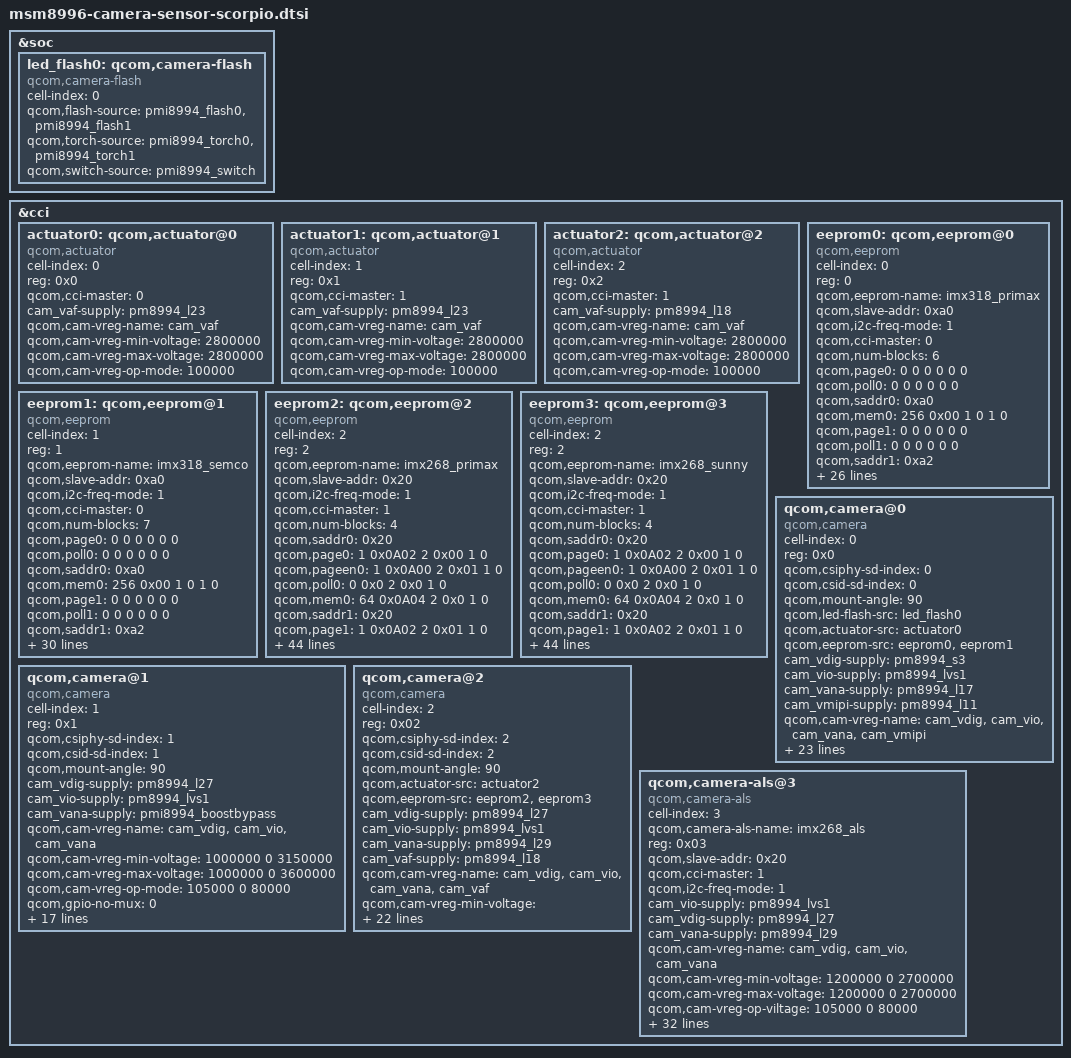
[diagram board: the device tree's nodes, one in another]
/*
 * Copyright (c) 2015-2016, The Linux Foundation. All rights reserved.
 * Copyright (C) 2016 XiaoMi, Inc.
 *
 * This program is free software; you can redistribute it and/or modify
 * it under the terms of the GNU General Public License version 2 and
 * only version 2 as published by the Free Software Foundation.
 *
 * This program is distributed in the hope that it will be useful,
 * but WITHOUT ANY WARRANTY; without even the implied warranty of
 * MERCHANTABILITY or FITNESS FOR A PARTICULAR PURPOSE.  See the
 * GNU General Public License for more details.
 */

&soc {
	led_flash0: qcom,camera-flash {
		cell-index = <0>;
		compatible = "qcom,camera-flash";
		qcom,flash-source = <&pmi8994_flash0 &pmi8994_flash1>;
		qcom,torch-source = <&pmi8994_torch0 &pmi8994_torch1>;
		qcom,switch-source = <&pmi8994_switch>;
	};
};

&cci {
	actuator0: qcom,actuator@0 {
		cell-index = <0>;
		reg = <0x0>;
		compatible = "qcom,actuator";
		qcom,cci-master = <0>;
		cam_vaf-supply = <&pm8994_l23>;
		qcom,cam-vreg-name = "cam_vaf";
		qcom,cam-vreg-min-voltage = <2800000>;
		qcom,cam-vreg-max-voltage = <2800000>;
		qcom,cam-vreg-op-mode = <100000>;
	};

	actuator1: qcom,actuator@1 {
		cell-index = <1>;
		reg = <0x1>;
		compatible = "qcom,actuator";
		qcom,cci-master = <1>;
		cam_vaf-supply = <&pm8994_l23>;
		qcom,cam-vreg-name = "cam_vaf";
		qcom,cam-vreg-min-voltage = <2800000>;
		qcom,cam-vreg-max-voltage = <2800000>;
		qcom,cam-vreg-op-mode = <100000>;
	};

	actuator2: qcom,actuator@2 {
		cell-index = <2>;
		reg = <0x2>;
		compatible = "qcom,actuator";
		qcom,cci-master = <1>;
		cam_vaf-supply = <&pm8994_l18>;
		qcom,cam-vreg-name = "cam_vaf";
		qcom,cam-vreg-min-voltage = <2800000>;
		qcom,cam-vreg-max-voltage = <2800000>;
		qcom,cam-vreg-op-mode = <100000>;
	};

	eeprom0: qcom,eeprom@0 {
		cell-index = <0>;
		reg = <0>;
		qcom,eeprom-name = "imx318_primax";
		compatible = "qcom,eeprom";
		qcom,slave-addr = <0xa0>;
		qcom,i2c-freq-mode = <1>;
		qcom,cci-master = <0>;
		qcom,num-blocks = <6>;

		qcom,page0 = <0 0 0 0 0 0>;
		qcom,poll0 = <0 0 0 0 0 0>;
		qcom,saddr0 = <0xa0>;
		qcom,mem0 = <256 0x00 1 0 1 0>;

		qcom,page1 = <0 0 0 0 0 0>;
		qcom,poll1 = <0 0 0 0 0 0>;
		qcom,saddr1 = <0xa2>;
		qcom,mem1 = <256 0x00 1 0 1 0>;

		qcom,page2 = <0 0 0 0 0 0>;
		qcom,poll2 = <0 0 0 0 0 0>;
		qcom,saddr2 = <0xa4>;
		qcom,mem2 = <256 0x00 1 0 1 0>;

		qcom,page3 = <0 0 0 0 0 0>;
		qcom,poll3 = <0 0 0 0 0 0>;
		qcom,saddr3 = <0xa6>;
		qcom,mem3 = <256 0x00 1 0 1 0>;

		qcom,page4 = <0 0 0 0 0 0>;
		qcom,poll4 = <0 0 0 0 0 0>;
		qcom,saddr4 = <0xa8>;
		qcom,mem4 = <256 0x00 1 0 1 0>;

		qcom,page5 = <0 0 0 0 0 0>;
		qcom,poll5 = <0 0 0 0 0 0>;
		qcom,saddr5 = <0xaa>;
		qcom,mem5 = <100 0x00 1 0 1 0>;

		cam_vio-supply = <&pm8994_lvs1>;
		qcom,cam-vreg-name = "cam_vio";
		qcom,cam-vreg-min-voltage = <0>;
		qcom,cam-vreg-max-voltage = <0>;
		qcom,cam-vreg-op-mode = <0>;
		qcom,cam-power-seq-type = "sensor_vreg";
		qcom,cam-power-seq-val = "cam_vio";
		qcom,cam-power-seq-cfg-val = <1>;
		qcom,cam-power-seq-delay = <1>;
	};

	eeprom1: qcom,eeprom@1 {
		cell-index = <1>;
		reg = <1>;
		qcom,eeprom-name = "imx318_semco";
		compatible = "qcom,eeprom";
		qcom,slave-addr = <0xa0>;
		qcom,i2c-freq-mode = <1>;
		qcom,cci-master = <0>;
		qcom,num-blocks = <7>;

		qcom,page0 = <0 0 0 0 0 0>;
		qcom,poll0 = <0 0 0 0 0 0>;
		qcom,saddr0 = <0xa0>;
		qcom,mem0 = <256 0x00 1 0 1 0>;

		qcom,page1 = <0 0 0 0 0 0>;
		qcom,poll1 = <0 0 0 0 0 0>;
		qcom,saddr1 = <0xa2>;
		qcom,mem1 = <256 0x00 1 0 1 0>;

		qcom,page2 = <0 0 0 0 0 0>;
		qcom,poll2 = <0 0 0 0 0 0>;
		qcom,saddr2 = <0xa4>;
		qcom,mem2 = <256 0x00 1 0 1 0>;

		qcom,page3 = <0 0 0 0 0 0>;
		qcom,poll3 = <0 0 0 0 0 0>;
		qcom,saddr3 = <0xa6>;
		qcom,mem3 = <256 0x00 1 0 1 0>;

		qcom,page4 = <0 0 0 0 0 0>;
		qcom,poll4 = <0 0 0 0 0 0>;
		qcom,saddr4 = <0xa8>;
		qcom,mem4 = <256 0x00 1 0 1 0>;

		qcom,page5 = <0 0 0 0 0 0>;
		qcom,poll5 = <0 0 0 0 0 0>;
		qcom,saddr5 = <0xaa>;
		qcom,mem5 = <256 0x00 1 0 1 0>;

		qcom,page6 = <0 0 0 0 0 0>;
		qcom,poll6 = <0 0 0 0 0 0>;
		qcom,saddr6 = <0xac>;
		qcom,mem6 = <256 0x00 1 0 1 0>;

		cam_vio-supply = <&pm8994_lvs1>;
		qcom,cam-vreg-name = "cam_vio";
		qcom,cam-vreg-min-voltage = <0>;
		qcom,cam-vreg-max-voltage = <0>;
		qcom,cam-vreg-op-mode = <0>;
		qcom,cam-power-seq-type = "sensor_vreg";
		qcom,cam-power-seq-val = "cam_vio";
		qcom,cam-power-seq-cfg-val = <1>;
		qcom,cam-power-seq-delay = <1>;
	};

	eeprom2: qcom,eeprom@2 {
		cell-index = <2>;
		reg = <2>;
		qcom,eeprom-name = "imx268_primax";
		compatible = "qcom,eeprom";
		qcom,slave-addr = <0x20>;
		qcom,i2c-freq-mode = <1>;
		qcom,cci-master = <1>;
		qcom,num-blocks = <4>;

		qcom,saddr0 = <0x20>;
		qcom,page0 = <1 0x0A02 2 0x00 1 0>;
		qcom,pageen0 = <1 0x0A00 2 0x01 1 0>;
		qcom,poll0 = <0 0x0 2 0x0 1 0>;
		qcom,mem0 = <64 0x0A04 2 0x0 1 0>;

	        qcom,saddr1 = <0x20>;
		qcom,page1 = <1 0x0A02 2 0x01 1 0>;
		qcom,pageen1 = <1 0x0A00 2 0x01 1 0>;
		qcom,poll1 = <0 0x0 2 0x0 1 0>;
		qcom,mem1 = <64 0x0A04 2 0x0 1 0>;

	        qcom,saddr2 = <0x20>;
		qcom,page2 = <1 0x0A02 2 0x02 1 0>;
		qcom,pageen2 = <1 0x0A00 2 0x01 1 0>;
		qcom,poll2 = <0 0x0 2 0x0 1 0>;
		qcom,mem2 = <64 0x0A04 2 0x0 1 0>;

	        qcom,saddr3 = <0x20>;
		qcom,page3 = <1 0x0A02 2 0x03 1 0>;
		qcom,pageen3 = <1 0x0A00 2 0x01 1 0>;
		qcom,poll3 = <0 0x0 2 0x0 1 0>;
		qcom,mem3 = <64 0x0A04 2 0x0 1 0>;

		cam_vdig-supply = <&pm8994_l27>;
		cam_vio-supply = <&pm8994_lvs1>;
		cam_vana-supply = <&pm8994_l29>;
		qcom,cam-vreg-name = "cam_vdig", "cam_vio", "cam_vana";
		qcom,cam-vreg-min-voltage = <1200000 0 2700000>;
		qcom,cam-vreg-max-voltage = <1200000 0 2700000>;
		qcom,cam-vreg-op-mode = <105000 0 80000>;
		qcom,gpio-no-mux = <0>;
		pinctrl-names = "cam_default", "cam_suspend";
		pinctrl-0 = <&cam_sensor_mclk2_active &cam_sensor_front_active>;
		pinctrl-1 = <&cam_sensor_mclk2_suspend &cam_sensor_front_suspend>;
		gpios = <&tlmm 15 0>,
			<&tlmm 23 0>,
			<&tlmm 26 0>;
		qcom,gpio-reset = <1>;
		qcom,gpio-standby = <2>;
		qcom,gpio-req-tbl-num = <0 1 2>;
		qcom,gpio-req-tbl-flags = <1 0 0>;
		qcom,gpio-req-tbl-label = "CAMIF_MCLK2",
					  "CAM_RESET2",
					  "VCM_PWDN";
		qcom,cam-power-seq-type = "sensor_vreg", "sensor_vreg", "sensor_vreg",
			"sensor_gpio", "sensor_gpio" , "sensor_clk";
		qcom,cam-power-seq-val = "cam_vdig", "cam_vana", "cam_vio",
			"sensor_gpio_reset", "sensor_gpio_standby","sensor_cam_mclk";
		qcom,cam-power-seq-cfg-val = <1 1 1 1 1 24000000>;
		qcom,cam-power-seq-delay = <1 1 1 30 30 5>;
		status = "ok";
		clocks = <&clock_mmss clk_mclk2_clk_src>,
			 <&clock_mmss clk_camss_mclk2_clk>;
		clock-names = "cam_src_clk", "cam_clk";
		qcom,clock-rates = <24000000 0>;
	};

	eeprom3: qcom,eeprom@3 {
		cell-index = <2>;
		reg = <2>;
		qcom,eeprom-name = "imx268_sunny";
		compatible = "qcom,eeprom";
		qcom,slave-addr = <0x20>;
		qcom,i2c-freq-mode = <1>;
		qcom,cci-master = <1>;
		qcom,num-blocks = <4>;

		qcom,saddr0 = <0x20>;
		qcom,page0 = <1 0x0A02 2 0x00 1 0>;
		qcom,pageen0 = <1 0x0A00 2 0x01 1 0>;
		qcom,poll0 = <0 0x0 2 0x0 1 0>;
		qcom,mem0 = <64 0x0A04 2 0x0 1 0>;

		qcom,saddr1 = <0x20>;
		qcom,page1 = <1 0x0A02 2 0x01 1 0>;
		qcom,pageen1 = <1 0x0A00 2 0x01 1 0>;
		qcom,poll1 = <0 0x0 2 0x0 1 0>;
		qcom,mem1 = <64 0x0A04 2 0x0 1 0>;

		qcom,saddr2 = <0x20>;
		qcom,page2 = <1 0x0A02 2 0x02 1 0>;
		qcom,pageen2 = <1 0x0A00 2 0x01 1 0>;
		qcom,poll2 = <0 0x0 2 0x0 1 0>;
		qcom,mem2 = <64 0x0A04 2 0x0 1 0>;

		qcom,saddr3 = <0x20>;
		qcom,page3 = <1 0x0A02 2 0x03 1 0>;
		qcom,pageen3 = <1 0x0A00 2 0x01 1 0>;
		qcom,poll3 = <0 0x0 2 0x0 1 0>;
		qcom,mem3 = <64 0x0A04 2 0x0 1 0>;

		cam_vdig-supply = <&pm8994_l27>;
		cam_vio-supply = <&pm8994_lvs1>;
		cam_vana-supply = <&pm8994_l29>;
		qcom,cam-vreg-name = "cam_vdig", "cam_vio", "cam_vana";
		qcom,cam-vreg-min-voltage = <1200000 0 2700000>;
		qcom,cam-vreg-max-voltage = <1200000 0 2700000>;
		qcom,cam-vreg-op-mode = <105000 0 80000>;
		qcom,gpio-no-mux = <0>;
		pinctrl-names = "cam_default", "cam_suspend";
		pinctrl-0 = <&cam_sensor_mclk2_active &cam_sensor_front_active>;
		pinctrl-1 = <&cam_sensor_mclk2_suspend &cam_sensor_front_suspend>;
		gpios = <&tlmm 15 0>,
			<&tlmm 23 0>,
			<&tlmm 26 0>;
		qcom,gpio-reset = <1>;
		qcom,gpio-standby = <2>;
		qcom,gpio-req-tbl-num = <0 1 2>;
		qcom,gpio-req-tbl-flags = <1 0 0>;
		qcom,gpio-req-tbl-label = "CAMIF_MCLK2",
					  "CAM_RESET2",
					  "VCM_PWDN";
		qcom,cam-power-seq-type = "sensor_vreg", "sensor_vreg", "sensor_vreg",
			"sensor_gpio", "sensor_gpio" , "sensor_clk";
		qcom,cam-power-seq-val = "cam_vdig", "cam_vana", "cam_vio",
			"sensor_gpio_reset", "sensor_gpio_standby","sensor_cam_mclk";
		qcom,cam-power-seq-cfg-val = <1 1 1 1 1 24000000>;
		qcom,cam-power-seq-delay = <1 1 1 30 30 5>;
		status = "ok";
		clocks = <&clock_mmss clk_mclk2_clk_src>,
			 <&clock_mmss clk_camss_mclk2_clk>;
		clock-names = "cam_src_clk", "cam_clk";
		qcom,clock-rates = <24000000 0>;
	};

	qcom,camera@0 {
		cell-index = <0>;
		compatible = "qcom,camera";
		reg = <0x0>;
		qcom,csiphy-sd-index = <0>;
		qcom,csid-sd-index = <0>;
		qcom,mount-angle = <90>;
		qcom,led-flash-src = <&led_flash0>;
		qcom,actuator-src = <&actuator0>;
		qcom,eeprom-src = <&eeprom0 &eeprom1>;
		cam_vdig-supply = <&pm8994_s3>;
		cam_vio-supply = <&pm8994_lvs1>;
		cam_vana-supply = <&pm8994_l17>;
                cam_vmipi-supply = <&pm8994_l11>;
		qcom,cam-vreg-name = "cam_vdig", "cam_vio", "cam_vana", "cam_vmipi";
		qcom,cam-vreg-min-voltage = <1300000 0 2800000 1100000>;
		qcom,cam-vreg-max-voltage = <1300000 0 2800000 1100000>;
		qcom,cam-vreg-op-mode = <105000 0 80000 105000>;
		qcom,gpio-no-mux = <0>;
		pinctrl-names = "cam_default", "cam_suspend";
		pinctrl-0 = <&cam_sensor_mclk0_active &cam_sensor_rear_active>;
		pinctrl-1 = <&cam_sensor_mclk0_suspend &cam_sensor_rear_suspend>;
		gpios = <&tlmm 13 0>,
			<&tlmm 86 0>,
			<&tlmm 30 0>;
		qcom,gpio-reset = <1>;
		qcom,gpio-standby = <2>;
		qcom,gpio-req-tbl-num = <0 1 2>;
		qcom,gpio-req-tbl-flags = <1 0 0>;
		qcom,gpio-req-tbl-label = "CAMIF_MCLK0",
					  "CAM_RESET0",
					  "CAM_STANDBY0";
		qcom,sensor-position = <0>;
		qcom,sensor-mode = <0>;
		qcom,cci-master = <0>;
		status = "ok";
		clocks = <&clock_mmss clk_mclk0_clk_src>,
				<&clock_mmss clk_camss_mclk0_clk>;
		clock-names = "cam_src_clk", "cam_clk";
		qcom,clock-rates = <24000000 0>;
	};

	qcom,camera@1 {
		cell-index = <1>;
		compatible = "qcom,camera";
		reg = <0x1>;
		qcom,csiphy-sd-index = <1>;
		qcom,csid-sd-index = <1>;
		qcom,mount-angle = <90>;
		cam_vdig-supply = <&pm8994_l27>;
		cam_vio-supply = <&pm8994_lvs1>;
		cam_vana-supply = <&pmi8994_boostbypass>;
		qcom,cam-vreg-name = "cam_vdig", "cam_vio", "cam_vana";
		qcom,cam-vreg-min-voltage = <1000000 0 3150000>;
		qcom,cam-vreg-max-voltage = <1000000 0 3600000>;
		qcom,cam-vreg-op-mode = <105000 0 80000>;
		qcom,gpio-no-mux = <0>;
		pinctrl-names = "cam_default", "cam_suspend";
		pinctrl-0 = <&cam_sensor_mclk1_active &cam_sensor_rear2_active>;
		pinctrl-1 = <&cam_sensor_mclk1_suspend &cam_sensor_rear2_suspend>;
		gpios = <&tlmm 14 0>,
			<&tlmm 63 0>,
			<&tlmm 62 0>;
		qcom,gpio-reset = <1>;
		qcom,gpio-standby = <2>;
		qcom,gpio-req-tbl-num = <0 1 2>;
		qcom,gpio-req-tbl-flags = <1 0 0>;
		qcom,gpio-req-tbl-label = "CAMIF_MCLK1",
					  "CAM_RESET1",
					  "CAM_STANDBY1";
		qcom,sensor-position = <0>;
		qcom,sensor-mode = <0>;
		qcom,cci-master = <0>;
		status = "ok";
		clocks = <&clock_mmss clk_mclk1_clk_src>,
			<&clock_mmss clk_camss_mclk1_clk>;
		clock-names = "cam_src_clk", "cam_clk";
		qcom,clock-rates = <24000000 0>;
	};

	qcom,camera@2 {
		cell-index = <2>;
		compatible = "qcom,camera";
		reg = <0x02>;
		qcom,csiphy-sd-index = <2>;
		qcom,csid-sd-index = <2>;
		qcom,mount-angle = <90>;
		qcom,actuator-src = <&actuator2>;
		qcom,eeprom-src = <&eeprom2 &eeprom3>;
		cam_vdig-supply = <&pm8994_l27>;
		cam_vio-supply = <&pm8994_lvs1>;
		cam_vana-supply = <&pm8994_l29>;
		cam_vaf-supply = <&pm8994_l18>;
		qcom,cam-vreg-name = "cam_vdig", "cam_vio", "cam_vana", "cam_vaf";
		qcom,cam-vreg-min-voltage = <1200000 0 2700000 2800000>;
		qcom,cam-vreg-max-voltage = <1200000 0 2700000 2800000>;
		qcom,cam-vreg-op-mode = <105000 0 80000 100000>;
		qcom,gpio-no-mux = <0>;
		pinctrl-names = "cam_default", "cam_suspend";
		pinctrl-0 = <&cam_sensor_mclk2_active &cam_sensor_front_active>;
		pinctrl-1 = <&cam_sensor_mclk2_suspend &cam_sensor_front_suspend>;
		gpios = <&tlmm 15 0>,
			<&tlmm 23 0>,
			<&tlmm 26 0>;
		qcom,gpio-reset = <1>;
		qcom,gpio-af-pwdm = <2>;/*qcom,gpio-standby = <2>;*/
		qcom,gpio-req-tbl-num = <0 1 2>;
		qcom,gpio-req-tbl-flags = <1 0 0>;
		qcom,gpio-req-tbl-label = "CAMIF_MCLK2",
					  "CAM_RESET2",
					  "VCM_PWDN";
		qcom,sensor-position = <1>;
		qcom,sensor-mode = <0>;
		qcom,cci-master = <1>;
		status = "ok";
		clocks = <&clock_mmss clk_mclk2_clk_src>,
			<&clock_mmss clk_camss_mclk2_clk>;
		clock-names = "cam_src_clk", "cam_clk";
		qcom,clock-rates = <24000000 0>;
	};

	qcom,camera-als@3 {
		cell-index = <3>;
		qcom,camera-als-name = "imx268_als";
		compatible = "qcom,camera-als";
		reg = <0x03>;
		qcom,slave-addr = <0x20>;
		qcom,cci-master = <1>;
		qcom,i2c-freq-mode = <1>;
		cam_vio-supply = <&pm8994_lvs1>;
		cam_vdig-supply = <&pm8994_l27>;
		cam_vana-supply = <&pm8994_l29>;
		qcom,cam-vreg-name = "cam_vdig","cam_vio","cam_vana";
		qcom,cam-vreg-min-voltage = <1200000 0 2700000>;
		qcom,cam-vreg-max-voltage = <1200000 0 2700000>;
		qcom,cam-vreg-op-viltage = <105000 0 80000>;
		pinctrl-names = "cam_default", "cam_suspend";
		pinctrl-0 = <&cam_sensor_mclk2_active &cam_sensor_front_active>;
		pinctrl-1 = <&cam_sensor_mclk2_suspend &cam_sensor_front_suspend>;
		qcom,gpio-no-mux = <0>;
		gpios = <&tlmm 15 0>,<&tlmm 23 0>,<&tlmm 26 0>;
		qcom,gpio-reset = <1>;
		qcom,gpio-standby = <2>;
		qcom,gpio-req-tbl-num = <0 1 2>;
		qcom,gpio-req-tbl-flags = <1 0 0>;
		qcom,gpio-req-tbl-label = "CAMIF_MCLK2","CAM_RESET2","CAM_STANDBY2";
		qcom,cam-power-seq-type = "sensor_gpio","sensor_gpio","sensor_vreg","sensor_vreg","sensor_vreg","sensor_clk","sensor_gpio";
		qcom,cam-power-seq-val = "sensor_gpio_standby","sensor_gpio_reset","cam_vana","cam_vdig","cam_vio","sensor_cam_mclk","sensor_gpio_reset";
		qcom,cam-power-seq-cfg-val = <1 0 2700000 1200000 0 24000000 1>;
		qcom,cam-power-seq-delay = <1 1 1 1 1 5 5>;
		qcom,cam-power-down-seq-type = "sensor_gpio","sensor_clk","sensor_vreg","sensor_vreg","sensor_vreg","sensor_gpio";
		qcom,cam-power-down-seq-val = "sensor_gpio_reset","sensor_cam_mclk","cam_vio","cam_vdig","cam_vana","sensor_gpio_standby";
		qcom,cam-power-down-seq-cfg-val = <0 0 0 0 0 0>;
		qcom,cam-power-down-seq-delay = <0 0 0 0 0 0>;
		status = "ok";
		clocks = <&clock_mmss clk_mclk2_clk_src>,
			<&clock_mmss clk_camss_mclk2_clk>;
		clock-names = "cam_src_clk", "cam_clk";
		qcom,clock-rates = <24000000 0>;
	};
};
